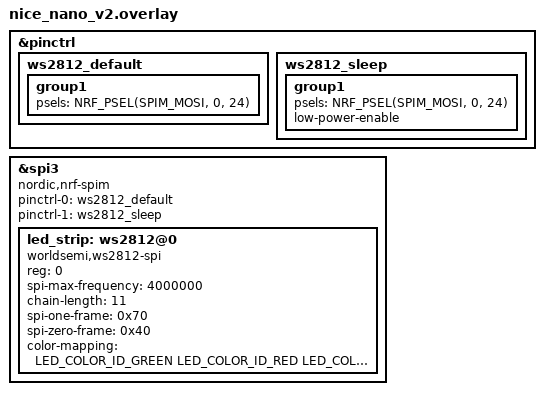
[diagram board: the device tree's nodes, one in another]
#include <dt-bindings/led/led.h>

&pinctrl {
    ws2812_default: ws2812_default {
        group1 {
            psels = <NRF_PSEL(SPIM_MOSI, 0, 24)>;
        };
    };

    ws2812_sleep: ws2812_sleep {
        group1 {
            psels = <NRF_PSEL(SPIM_MOSI, 0, 24)>;
            low-power-enable;
        };
    };
};

&spi3 {
  compatible = "nordic,nrf-spim";
  status = "okay";

  pinctrl-0 = <&ws2812_default>;
  pinctrl-1 = <&ws2812_sleep>;
  pinctrl-names = "default", "sleep";

  led_strip: ws2812@0 {
    compatible = "worldsemi,ws2812-spi";

    /* SPI */
    reg = <0>; /* ignored, but necessary for SPI bindings */
    spi-max-frequency = <4000000>;

    /* WS2812 */
    chain-length = <11>; /* number of LEDs */
    spi-one-frame = <0x70>;
    spi-zero-frame = <0x40>;
    color-mapping = <LED_COLOR_ID_GREEN
                          LED_COLOR_ID_RED
                          LED_COLOR_ID_BLUE>;
  };
};
